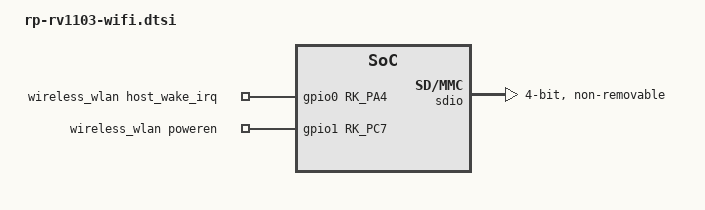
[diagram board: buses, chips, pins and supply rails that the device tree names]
/{
    wireless_wlan: wireless-wlan {
        compatible = "wlan-platdata";
        wifi_chip_type = "ap6212";
        pinctrl-names = "default";
        pinctrl-0 = <&wifi_host_wake_irq>, <&wifi_enable_h>;
        WIFI,host_wake_irq = <&gpio0 RK_PA4 GPIO_ACTIVE_HIGH>;
        WIFI,poweren_gpio = <&gpio1 RK_PC7 GPIO_ACTIVE_HIGH>;
        clocks = <&hym8563>; //use hym8563 out 32.768k clk
        clock-names = "rtc_32k";
        status = "okay";
    };

    sdio_pwrseq: sdio-pwrseq {
        status = "disabled";
        compatible = "mmc-pwrseq-simple";
        pinctrl-names = "default";
        pinctrl-0 = <&wifi_enable_h>;

        /*
         * On the module itself this is one of these (depending
         * on the actual card populated):
         * - SDIO_RESET_L_WL_REG_ON
         * - PDN (power down when low)
         */
        post-power-on-delay-ms = <300>;
        reset-gpios = <&gpio1 RK_PC7 GPIO_ACTIVE_LOW>;
    };
};

&sdio {
    max-frequency = <150000000>;
    no-sd;
    no-mmc;
    bus-width = <4>;
    cap-sd-highspeed;
    cap-sdio-irq;
    keep-power-in-suspend;
    //mmc-pwrseq = <&sdio_pwrseq>; // sdio can not pull up gpio
    non-removable;
    sd-uhs-sdr104;
    pinctrl-names = "default";
    pinctrl-0 = <&sdmmc1m1_cmd &sdmmc1m1_clk &sdmmc1m1_bus4>;
    status = "okay";
};

&pinctrl {
    sdio-pwrseq {
        wifi_enable_h: wifi-enable-h {
            rockchip,pins = <1 RK_PC7 RK_FUNC_GPIO &pcfg_pull_none>;
        };
    };

    wireless-wlan {
        wifi_host_wake_irq: wifi-host-wake-irq {
            rockchip,pins = <0 RK_PA4 RK_FUNC_GPIO &pcfg_pull_down>;
        };
    };
};
